AUTOSAR XML (schema 00046)
package /ComponentTypes
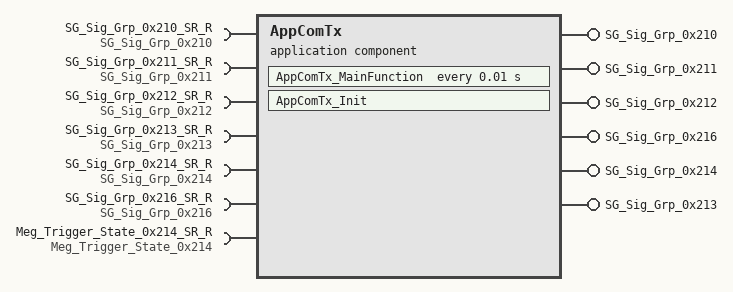
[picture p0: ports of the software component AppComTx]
  application sw component type AppComTx
    6 x provide port:
      SG_Sig_Grp_0x210: nonqueued-sender-com-spec{data-element=SG_Sig_Grp_0x210, init-value=fields=[F_Led1_State:0, F_Led2_State:0, F_Led3_State:0, F_Led4_State:0]}, provided-interface=SG_Sig_Grp_0x210
      SG_Sig_Grp_0x211: nonqueued-sender-com-spec{data-element=SG_Sig_Grp_0x211, init-value=fields=[F_Button1_State:0, F_Button2_State:0, F_Button3_State:0, F_Button4_State:0]}, provided-interface=SG_Sig_Grp_0x211
      SG_Sig_Grp_0x212: nonqueued-sender-com-spec{data-element=SG_Sig_Grp_0x212, init-value=fields=[F_PowerMode:0, SupF_Checksum_0x212:0, SupF_Counter_0x212:0]}, provided-interface=SG_Sig_Grp_0x212
      SG_Sig_Grp_0x216: nonqueued-sender-com-spec{data-element=SG_Sig_Grp_0x216, init-value=fields=[F_Meg_E2E_Error:0, F_Mes_Lost_Error:0]}, provided-interface=SG_Sig_Grp_0x216
      SG_Sig_Grp_0x214: nonqueued-sender-com-spec{data-element=SG_Sig_Grp_0x214, init-value=fields=[F_Sig_0x214_Used_1:0, F_Sig_0x214_Used_2:0, F_Sig_0x214_Used_3:0, F_Sig_0x214_Used_5:0]}, provided-interface=SG_Sig_Grp_0x214
      SG_Sig_Grp_0x213: nonqueued-sender-com-spec{data-element=SG_Sig_Grp_0x213, init-value=fields=F_AAA_Angle:36}, provided-interface=SG_Sig_Grp_0x213
    7 x require port:
      SG_Sig_Grp_0x210_SR_R: nonqueued-receiver-com-spec{data-element=SG_Sig_Grp_0x210, filter=data-filter-type=ALWAYS, init-value=fields=[F_Led1_State:0, F_Led2_State:0, F_Led3_State:0, F_Led4_State:0]}, required-interface=SG_Sig_Grp_0x210
      SG_Sig_Grp_0x211_SR_R: nonqueued-receiver-com-spec{data-element=SG_Sig_Grp_0x211, filter=data-filter-type=ALWAYS, init-value=fields=[F_Button1_State:0, F_Button2_State:0, F_Button3_State:0, F_Button4_State:0]}, required-interface=SG_Sig_Grp_0x211
      SG_Sig_Grp_0x212_SR_R: nonqueued-receiver-com-spec{data-element=SG_Sig_Grp_0x212, filter=data-filter-type=ALWAYS, init-value=fields=[F_PowerMode:0, SupF_Checksum_0x212:0, SupF_Counter_0x212:0]}, required-interface=SG_Sig_Grp_0x212
      SG_Sig_Grp_0x213_SR_R: nonqueued-receiver-com-spec{data-element=SG_Sig_Grp_0x213, filter=data-filter-type=ALWAYS, init-value=fields=F_AAA_Angle:36}, required-interface=SG_Sig_Grp_0x213
      SG_Sig_Grp_0x214_SR_R: nonqueued-receiver-com-spec{data-element=SG_Sig_Grp_0x214, filter=data-filter-type=ALWAYS, init-value=fields=[F_Sig_0x214_Used_1:0, F_Sig_0x214_Used_2:0, F_Sig_0x214_Used_3:0, F_Sig_0x214_Used_5:0]}, required-interface=SG_Sig_Grp_0x214
      SG_Sig_Grp_0x216_SR_R: nonqueued-receiver-com-spec{data-element=SG_Sig_Grp_0x216, filter=data-filter-type=ALWAYS, init-value=fields=[F_Meg_E2E_Error:0, F_Mes_Lost_Error:0]}, required-interface=SG_Sig_Grp_0x216
      Meg_Trigger_State_0x214_SR_R: nonqueued-receiver-com-spec{data-element=Meg_Trigger_State, filter=data-filter-type=ALWAYS}, required-interface=Meg_Trigger_State_0x214
    behavior AppComTx_InternalBehavior
      init event AppComTx_InitEvent: start-on-event=AppComTx_Init
      timing event TMT_AppComTx_MainFunction: start-on-event=AppComTx_MainFunction, period=0.01
      runnable AppComTx_Init
      runnable AppComTx_MainFunction
        data-receive-point-by-arguments:
          7 x access:
            REC_SG_Sig_Grp_0x{210..214}_SR_R_SG_Sig_Grp_0x{210..214}: accessed-variable=SG_Sig_Grp_0x{210..214}_SR_R.SG_Sig_Grp_0x{210..214}
            REC_SG_Sig_Grp_0x216_SR_R_SG_Sig_Grp_0x216: accessed-variable=SG_Sig_Grp_0x216_SR_R.SG_Sig_Grp_0x216
            REC_Meg_Trigger_State_0x214_SR_R_Meg_Trigger_State: accessed-variable=Meg_Trigger_State_0x214_SR_R.Meg_Trigger_State
        data-send-points:
          6 x access:
            SEND_SG_Sig_Grp_0x{210..214}_SG_Sig_Grp_0x{210..214}: accessed-variable=SG_Sig_Grp_0x{210..214}.SG_Sig_Grp_0x{210..214}
            SEND_SG_Sig_Grp_0x216_SG_Sig_Grp_0x216: accessed-variable=SG_Sig_Grp_0x216.SG_Sig_Grp_0x216
  swc implementation AppComTx_Implementation: behavior=AppComTx_InternalBehavior
